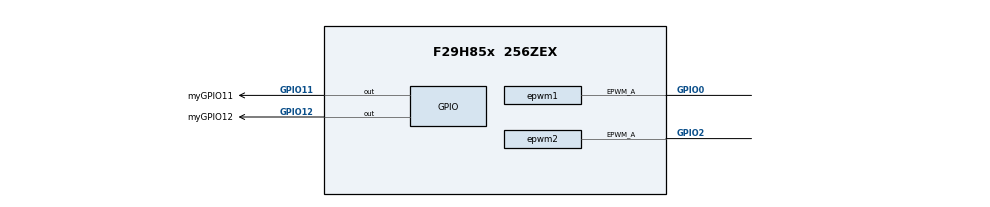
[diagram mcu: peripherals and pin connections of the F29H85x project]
/**
 * @cliArgs --device "F29H85x" --package "256ZEX" --part "F29H85x_256ZEX" --context "CPU1" --product "MCU_SDK_F29H85x@1.02.02.00"
 * @versions {"tool":"1.25.0+4237"}
 */

    
const divider15       = system.clockTree["PLL_REFDIV"];
divider15.divideValue = 1;

const multiplier1         = system.clockTree["PLL_IMULT"];
multiplier1.multiplyValue = 40;

const mux7       = system.clockTree["OSCCLKSRCSEL"];
mux7.inputSelect = "INTOSC2";

/**
 * Import the modules used in this configuration.
 */
const jtag  = scripting.addModule("/driverlib/jtag.js");
const epwm             = scripting.addModule("/driverlib/epwm.js", {}, false);
const epwm1            = epwm.addInstance();
const epwm2            = epwm.addInstance();
const gpio             = scripting.addModule("/driverlib/gpio.js", {}, false);
const gpio1            = gpio.addInstance();
const gpio2            = gpio.addInstance();
const inputxbar_input  = scripting.addModule("/driverlib/inputxbar_input.js", {}, false);
const inputxbar_input1 = inputxbar_input.addInstance();

/**
 * Write custom configuration values to the imported modules.
 */
epwm1.$name                                                      = "myEPWM1";
epwm1.epwmTimebase_clockDiv                                      = "EPWM_CLOCK_DIVIDER_4";
epwm1.epwmTimebase_hsClockDiv                                    = "EPWM_HSCLOCK_DIVIDER_4";
epwm1.epwmTimebase_counterMode                                   = "EPWM_COUNTER_MODE_UP_DOWN";
epwm1.epwmCounterCompare_cmpA                                    = 6000;
epwm1.epwmTimebase_period                                        = 12000;
epwm1.epwmActionQualifier_EPWM_AQ_OUTPUT_A_ON_TIMEBASE_UP_CMPA   = "EPWM_AQ_OUTPUT_HIGH";
epwm1.epwmActionQualifier_EPWM_AQ_OUTPUT_A_ON_TIMEBASE_DOWN_CMPA = "EPWM_AQ_OUTPUT_LOW";
epwm1.epwmTripZone_EPWM_TZ_ACTION_EVENT_TZA                      = "EPWM_TZ_ACTION_HIGH";
epwm1.epwmTripZone_oneShotSource                                 = ["EPWM_TZ_SIGNAL_OSHT1"];
epwm1.epwmTripZone_tzInterruptSource                             = ["EPWM_TZ_INTERRUPT_OST"];
epwm1.epwmTripZone_registerInterrupts                            = true;
epwm1.useCase                                                    = "CUSTOM";
epwm1.useInterfacePins                                           = ["EPWM#_A"];
epwm1.epwmTZInt.interruptHandler                                 = "epwm1TZISR";
epwm1.epwm.$assign                                               = "EPWM1";
epwm1.epwm.epwm_aPin.$assign                                     = "GPIO0";

epwm2.$name                                                      = "myEPWM2";
epwm2.useCase                                                    = "CUSTOM";
epwm2.useInterfacePins                                           = ["EPWM#_A"];
epwm2.epwmTimebase_clockDiv                                      = "EPWM_CLOCK_DIVIDER_4";
epwm2.epwmTimebase_hsClockDiv                                    = "EPWM_HSCLOCK_DIVIDER_4";
epwm2.epwmTimebase_period                                        = 6000;
epwm2.epwmTimebase_counterMode                                   = "EPWM_COUNTER_MODE_UP_DOWN";
epwm2.epwmCounterCompare_cmpA                                    = 3000;
epwm2.epwmActionQualifier_EPWM_AQ_OUTPUT_A_ON_TIMEBASE_UP_CMPA   = "EPWM_AQ_OUTPUT_HIGH";
epwm2.epwmActionQualifier_EPWM_AQ_OUTPUT_A_ON_TIMEBASE_DOWN_CMPA = "EPWM_AQ_OUTPUT_LOW";
epwm2.epwmTripZone_EPWM_TZ_ACTION_EVENT_TZA                      = "EPWM_TZ_ACTION_HIGH";
epwm2.epwmTripZone_cbcSource                                     = ["EPWM_TZ_SIGNAL_CBC1"];
epwm2.epwmTripZone_tzInterruptSource                             = ["EPWM_TZ_INTERRUPT_CBC"];
epwm2.epwmTripZone_registerInterrupts                            = true;
epwm2.epwm.$assign                                               = "EPWM2";
epwm2.epwm.epwm_aPin.$assign                                     = "GPIO2";
epwm2.epwmTZInt.interruptHandler                                 = "epwm2TZISR";

gpio1.$name           = "myGPIO11";
gpio1.direction       = "GPIO_DIR_MODE_OUT";
gpio1.qualMode        = "GPIO_QUAL_ASYNC";
gpio1.gpioPin.$assign = "GPIO11";

gpio2.$name           = "myGPIO12";
gpio2.qualMode        = "GPIO_QUAL_ASYNC";
gpio2.padConfig       = "PULLUP";
gpio2.direction       = "GPIO_DIR_MODE_OUT";
gpio2.gpioPin.$assign = "GPIO12";

inputxbar_input1.$name         = "myINPUTXBARINPUT0";
inputxbar_input1.inputxbarGpio = "GPIO12";
